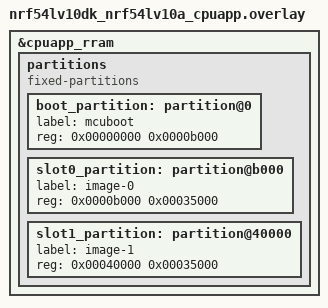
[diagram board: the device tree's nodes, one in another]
/*
 * Copyright (c) 2026 Nordic Semiconductor ASA
 *
 * SPDX-License-Identifier: LicenseRef-Nordic-5-Clause
 */

/delete-node/ &boot_partition;
/delete-node/ &slot0_partition;
/delete-node/ &slot1_partition;

&cpuapp_rram {
	partitions {
		compatible = "fixed-partitions";
		#address-cells = <1>;
		#size-cells = <1>;

		boot_partition: partition@0 {
			label = "mcuboot";
			reg = <0x00000000 0x0000b000>;
		};

		slot0_partition: partition@b000 {
			label = "image-0";
			reg = <0x0000b000 0x00035000>;
		};

		slot1_partition: partition@40000 {
			label = "image-1";
			reg = <0x00040000 0x00035000>;
		};
	};
};
